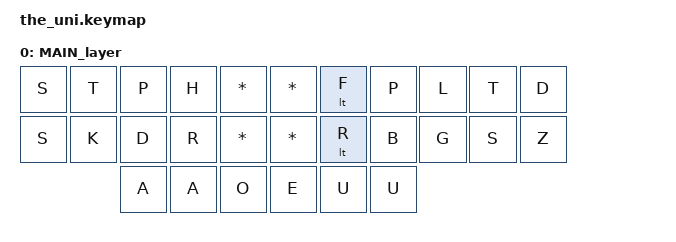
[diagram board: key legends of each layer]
/*
* Copyright (c) 2021 The ZMK Contributors
*
* SPDX-License-Identifier: MIT
*/

#include <behaviors.dtsi>
#include <dt-bindings/zmk/keys.h>

#define MAIN 0

/ {
    keymap {
        compatible = "zmk,keymap";

        MAIN_layer {
            bindings = <
                &kp S    &kp T    &kp P    &kp H    &kp STAR      &kp STAR &lt F    &kp P    &kp L    &kp T    &kp D
                &kp S    &kp K    &kp D    &kp R    &kp STAR      &kp STAR &lt R    &kp B    &kp G    &kp S    &kp Z
                                  &kp A    &kp A    &kp O         &kp E    &kp U    &kp U
            >;
        };
    };
};
